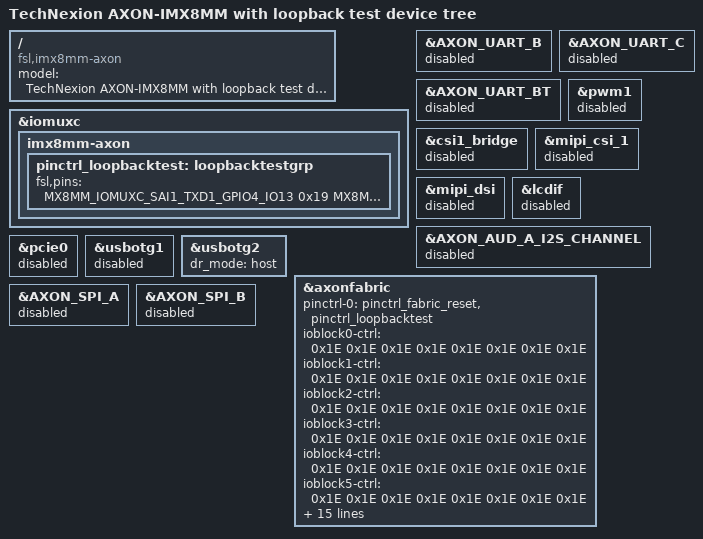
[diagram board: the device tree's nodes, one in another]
/*
 * Copyright 2019 Technexion Ltd.
 * Copyright 2018 NXP
 *
 * Author: Richard Hu <richard.hu@technexion.com>
 *         John Weber <john.weber@technexion.com>
 *
 * This program is free software; you can redistribute it and/or
 * modify it under the terms of the GNU General Public License
 * as published by the Free Software Foundation; either version 2
 * of the License, or (at your option) any later version.
 *
 * This program is distributed in the hope that it will be useful,
 * but WITHOUT ANY WARRANTY; without even the implied warranty of
 * MERCHANTABILITY or FITNESS FOR A PARTICULAR PURPOSE.  See the
 * GNU General Public License for more details.
 *
 * Axon device tree configurations for internal loopback testing
 * between the axon fabric and the i.MX8M Mini.
 *
 */

/dts-v1/;

#include "imx8mm-axon.dtsi"

/ {
	model = "TechNexion AXON-IMX8MM with loopback test device tree";
	compatible = "fsl,imx8mm-axon", "fsl,imx8mm";

};

&iomuxc {

	imx8mm-axon {

		pinctrl_loopbacktest: loopbacktestgrp {
			fsl,pins = <
				MX8MM_IOMUXC_SAI1_TXD1_GPIO4_IO13			0x19  /* GPIO_X1_P66 */
				MX8MM_IOMUXC_SAI1_MCLK_GPIO4_IO20			0x19  /* GPIO_SPARE1 */
				MX8MM_IOMUXC_SPDIF_EXT_CLK_GPIO5_IO5		0x19  /* PWM1 */
				MX8MM_IOMUXC_SAI3_RXC_GPIO4_IO29			0x19  /* UART_B_CTS */
				MX8MM_IOMUXC_SAI3_TXD_GPIO5_IO1		    	0x19  /* GPIO_X3_P67 */
				MX8MM_IOMUXC_SAI2_TXD0_GPIO4_IO26		    0x19  /* GPIO_X3_P65 */
				MX8MM_IOMUXC_GPIO1_IO14_GPIO1_IO14			0x19  /* GPIO_X3_P69 */
				MX8MM_IOMUXC_SPDIF_RX_GPIO5_IO4				0x19  /* PWM2 / DSI RST */
				MX8MM_IOMUXC_SAI1_RXD7_GPIO4_IO9			0x19  /* GPIO_X2_P20, Touch INT */
				MX8MM_IOMUXC_SAI5_RXFS_GPIO3_IO19			0x19  /* AUD_B_RXFS */
				MX8MM_IOMUXC_SAI5_MCLK_GPIO3_IO25			0x19  /* AUD_B_MCLK */
				MX8MM_IOMUXC_SAI5_RXC_GPIO3_IO20			0x19  /* AUD_B_RXC */
				MX8MM_IOMUXC_SAI5_RXD0_GPIO3_IO21			0x19  /* AUD_B_RXD */
				MX8MM_IOMUXC_SAI5_RXD1_GPIO3_IO22			0x19  /* AUD_B_TXFS */
				MX8MM_IOMUXC_SAI5_RXD2_GPIO3_IO23			0x19  /* AUD_B_TXC */
				MX8MM_IOMUXC_SAI5_RXD3_GPIO3_IO24			0x19  /* AUD_B_TXD */
				MX8MM_IOMUXC_SAI3_MCLK_GPIO5_IO2			0x19  /* PWM4 */
				MX8MM_IOMUXC_SAI3_TXFS_GPIO4_IO31			0x19  /* UART_B_RXD */
				MX8MM_IOMUXC_SAI3_TXC_GPIO5_IO0				0x19  /* UART_B_TXD */
				MX8MM_IOMUXC_SAI3_RXFS_GPIO4_IO28			0x19  /* GPIO_X3_P71 */
				MX8MM_IOMUXC_SAI3_RXC_GPIO4_IO29			0x19  /* UART_B_CTS */
				MX8MM_IOMUXC_SAI3_RXD_GPIO4_IO30			0x19  /* UART_B_RTS */
				MX8MM_IOMUXC_SPDIF_TX_GPIO5_IO3				0x19  /* PWM3 */
				MX8MM_IOMUXC_SAI1_TXD2_GPIO4_IO14			0x19  /* GPIO_X1_P68 */
				MX8MM_IOMUXC_SAI1_TXD3_GPIO4_IO15			0x19  /* GPIO_X1_P70 */
				MX8MM_IOMUXC_SAI1_TXD4_GPIO4_IO16			0x19  /* GPIO_X1_P72 */
				MX8MM_IOMUXC_SAI1_TXD5_GPIO4_IO17			0x19  /* AUD_BT_RXD */
				MX8MM_IOMUXC_SAI1_TXD6_GPIO4_IO18			0x19  /* GPIO_X1_P74 */
				MX8MM_IOMUXC_SAI1_TXD7_GPIO4_IO19 			0x19  /* GPIO_X1_P76 */
				MX8MM_IOMUXC_SAI1_RXFS_GPIO4_IO0			0x19  /* GPIO_X2_P22 */
				MX8MM_IOMUXC_SAI1_RXC_GPIO4_IO1				0x19  /* GPIO_X2_P24 */
				MX8MM_IOMUXC_SAI1_RXD0_GPIO4_IO2			0x19  /* AUD_A_RXD */
				MX8MM_IOMUXC_SAI1_RXD1_GPIO4_IO3 			0x19  /* GPIO_X1_P78 */
				MX8MM_IOMUXC_SAI1_RXD2_GPIO4_IO4			0x19  /* GPIO_X1_P80 */
				MX8MM_IOMUXC_SAI1_RXD3_GPIO4_IO5			0x19  /* GPIO_X2_P18 */
				MX8MM_IOMUXC_SAI1_RXD4_GPIO4_IO6			0x19  /* AUD_BT_TXC */
				MX8MM_IOMUXC_SAI1_RXD5_GPIO4_IO7			0x19  /* AUD_BT_TXD */
				MX8MM_IOMUXC_SAI1_RXD6_GPIO4_IO8			0x19  /* AUD_BT_TXFS */
				MX8MM_IOMUXC_SAI1_RXD7_GPIO4_IO9			0x19  /* GPIO_X2_P20 */
				MX8MM_IOMUXC_SAI2_TXFS_GPIO4_IO24 			0x19  /* UART_A_CTS */
				MX8MM_IOMUXC_SAI2_RXD0_GPIO4_IO23			0x19  /* UART_A_RTS */
				MX8MM_IOMUXC_ECSPI1_SCLK_GPIO5_IO6			0x19  /* SPI_A_SCLK */
				MX8MM_IOMUXC_ECSPI1_MISO_GPIO5_IO8			0x19  /* SPI_A_MISO */
				MX8MM_IOMUXC_ECSPI1_MOSI_GPIO5_IO7			0x19  /* SPI_A_MOSI */
				MX8MM_IOMUXC_ECSPI1_SS0_GPIO5_IO9			0x19  /* SPI_A_CS0 */
				MX8MM_IOMUXC_ECSPI2_SCLK_GPIO5_IO10			0x19  /* UART_BT_RXD */
				MX8MM_IOMUXC_ECSPI2_MISO_GPIO5_IO12			0x19  /* UART_BT_CTS */
				MX8MM_IOMUXC_ECSPI2_MOSI_GPIO5_IO11			0x19  /* UART_BT_TXD */
				MX8MM_IOMUXC_ECSPI2_SS0_GPIO5_IO13			0x19  /* UART_BT_RTS */
				MX8MM_IOMUXC_GPIO1_IO08_GPIO1_IO8			0x19  /* SPI_A_CS1 */
				MX8MM_IOMUXC_GPIO1_IO09_GPIO1_IO9			0x19  /* SPI_B_CS1 */
				MX8MM_IOMUXC_UART1_RXD_GPIO5_IO22			0x19  /* SPI_B_SCLK */
				MX8MM_IOMUXC_UART1_TXD_GPIO5_IO23			0x19  /* SPI_B_MOSI */
				MX8MM_IOMUXC_UART2_RXD_GPIO5_IO24			0x19  /* SPI_B_MISO */
				MX8MM_IOMUXC_UART2_TXD_GPIO5_IO25			0x19  /* SPI_B_CS0 */
				MX8MM_IOMUXC_UART3_RXD_GPIO5_IO26			0x19  /* UART_C_RXD */
				MX8MM_IOMUXC_UART3_TXD_GPIO5_IO27			0x19  /* UART_C_TXD */
				MX8MM_IOMUXC_SAI1_TXD0_GPIO4_IO12			0x19  /* AUD_A_TXD */
				MX8MM_IOMUXC_SAI1_TXFS_GPIO4_IO10			0x19  /* AUD_A_TXFS */
				MX8MM_IOMUXC_SAI1_TXC_GPIO4_IO11			0x19  /* AUD_A_TXCLK */
			>;
		};
	};
};

&AXON_UART_B {
	status = "disabled";
};

&AXON_UART_C {
	status = "disabled";
};

&AXON_UART_BT {
	status = "disabled";
};

&pwm1 {
	status = "disabled";
};


&csi1_bridge {
	status = "disabled";
};

&mipi_csi_1 {
	status = "disabled";
};

&mipi_dsi {
	status = "disabled";
};

&lcdif {
	status = "disabled";
};

&AXON_AUD_A_I2S_CHANNEL {  // AUD_A
	status = "disabled";
};

&pcie0{
	status = "disabled";
};

&usbotg1 {
	status = "disabled";
};

&usbotg2 {
	dr_mode = "host";
	status = "okay";
};

&pwm1 {
	status = "disabled";
};

&axonfabric {
	pinctrl-0 = <
		&pinctrl_fabric_reset
		&pinctrl_loopbacktest
	>;

	ioblock0-ctrl =  /bits/ 8 <0x1E 0x1E 0x1E 0x1E 0x1E 0x1E 0x1E 0x1E>;
	ioblock1-ctrl =  /bits/ 8 <0x1E 0x1E 0x1E 0x1E 0x1E 0x1E 0x1E 0x1E>;
	ioblock2-ctrl =  /bits/ 8 <0x1E 0x1E 0x1E 0x1E 0x1E 0x1E 0x1E 0x1E>;
	ioblock3-ctrl =  /bits/ 8 <0x1E 0x1E 0x1E 0x1E 0x1E 0x1E 0x1E 0x1E>;
	ioblock4-ctrl =  /bits/ 8 <0x1E 0x1E 0x1E 0x1E 0x1E 0x1E 0x1E 0x1E>;
	ioblock5-ctrl =  /bits/ 8 <0x1E 0x1E 0x1E 0x1E 0x1E 0x1E 0x1E 0x1E>;
	ioblock6-ctrl =  /bits/ 8 <0x1E 0x1E 0x1E 0x1E 0x1E 0x1E 0x1E 0x1E>;
	ioblock7-ctrl =  /bits/ 8 <0x1E 0x1E 0x1E 0x1E 0x1E 0x1E 0x1E 0x1E>;
	ioblock8-ctrl =  /bits/ 8 <0x1E 0x1E 0x1E 0x1E 0x1E 0x1E 0x1E 0x1E>;
	ioblock9-ctrl =  /bits/ 8 <0x1E 0x1E 0x1E 0x1E 0x1E 0x1E 0x1E 0x1E>;
	ioblock10-ctrl = /bits/ 8 <0x1E 0x1E 0x1E 0x1E 0x1E 0x1E 0x1E 0x1E>;
	ioblock11-ctrl = /bits/ 8 <0x1E 0x1E 0x1E 0x1E 0x1E 0x1E 0x1E 0x1E>;
	ioblock12-ctrl = /bits/ 8 <0x1E 0x1E 0x1E 0x1E 0x1E 0x1E 0x1E 0x1E>;

 	lock-direction;
};

&AXON_SPI_A {
	status = "disabled";
};

&AXON_SPI_B {
	status = "disabled";
};
